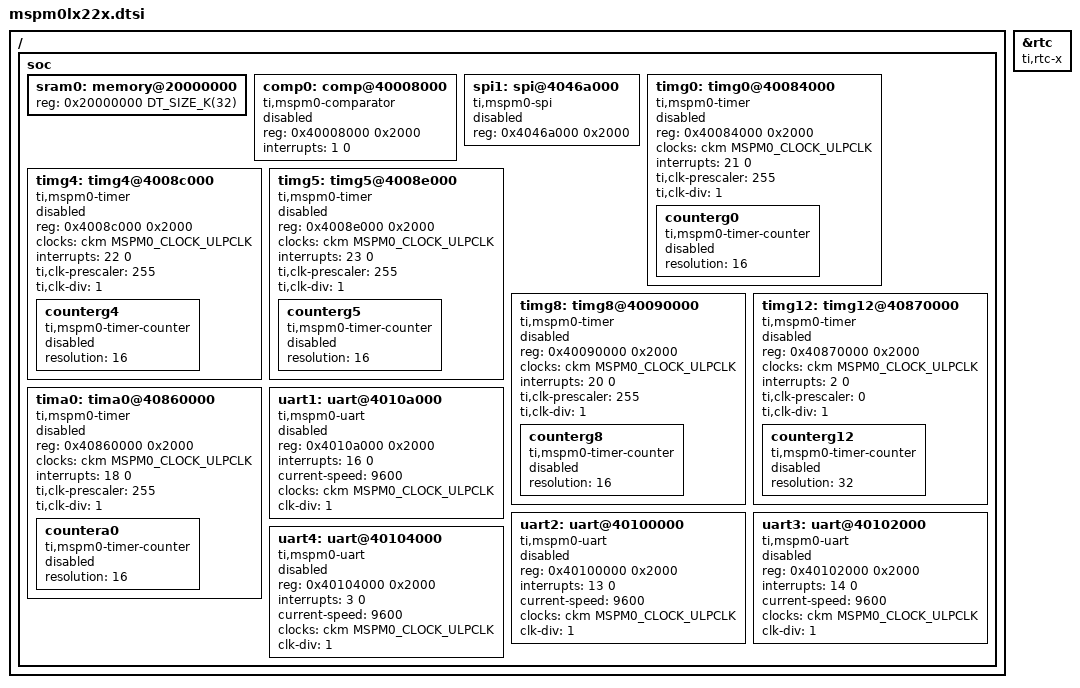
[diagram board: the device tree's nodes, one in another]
/*
 * Copyright (c) 2025-2026 Texas Instruments
 * Copyright (c) 2025 Linumiz GmbH
 *
 * SPDX-License-Identifier: Apache-2.0
 */

#include <mem.h>
#include <ti/mspm0/l/mspm0l.dtsi>

/ {
	soc {
		sram0: memory@20000000 {
			reg = <0x20000000 DT_SIZE_K(32)>;
		};

		comp0: comp@40008000 {
			compatible = "ti,mspm0-comparator";
			reg = <0x40008000 0x2000>;
			interrupts = <1 0>;
			status = "disabled";
		};

		spi1: spi@4046a000 {
			compatible = "ti,mspm0-spi";
			reg = <0x4046a000 0x2000>;
			status = "disabled";
		};

		timg0: timg0@40084000 {
			compatible = "ti,mspm0-timer";
			reg = <0x40084000 0x2000>;
			clocks = <&ckm MSPM0_CLOCK_ULPCLK>;
			interrupts = <21 0>;
			ti,clk-prescaler = <255>;
			ti,clk-div = <1>;
			status = "disabled";

			counterg0: counterg0 {
				compatible = "ti,mspm0-timer-counter";
				resolution = <16>;
				status = "disabled";
			};
		};

		timg4: timg4@4008c000 {
			compatible = "ti,mspm0-timer";
			reg = <0x4008c000 0x2000>;
			clocks = <&ckm MSPM0_CLOCK_ULPCLK>;
			interrupts = <22 0>;
			ti,clk-prescaler = <255>;
			ti,clk-div = <1>;
			status = "disabled";

			counterg4: counterg4 {
				compatible = "ti,mspm0-timer-counter";
				resolution = <16>;
				status = "disabled";
			};
		};

		timg5: timg5@4008e000 {
			compatible = "ti,mspm0-timer";
			reg = <0x4008e000 0x2000>;
			clocks = <&ckm MSPM0_CLOCK_ULPCLK>;
			interrupts = <23 0>;
			ti,clk-prescaler = <255>;
			ti,clk-div = <1>;
			status = "disabled";

			counterg5: counterg5 {
				compatible = "ti,mspm0-timer-counter";
				resolution = <16>;
				status = "disabled";
			};
		};

		timg8: timg8@40090000 {
			compatible = "ti,mspm0-timer";
			reg = <0x40090000 0x2000>;
			clocks = <&ckm MSPM0_CLOCK_ULPCLK>;
			interrupts = <20 0>;
			ti,clk-prescaler = <255>;
			ti,clk-div = <1>;
			status = "disabled";

			counterg8: counterg8 {
				compatible = "ti,mspm0-timer-counter";
				resolution = <16>;
				status = "disabled";
			};
		};

		timg12: timg12@40870000 {
			compatible = "ti,mspm0-timer";
			reg = <0x40870000 0x2000>;
			clocks = <&ckm MSPM0_CLOCK_ULPCLK>;
			interrupts = <2 0>;
			ti,clk-prescaler = <0>; /* No prescaler */
			ti,clk-div = <1>;
			status = "disabled";

			counterg12: counterg12 {
				compatible = "ti,mspm0-timer-counter";
				resolution = <32>;
				status = "disabled";
			};
		};

		tima0: tima0@40860000 {
			compatible = "ti,mspm0-timer";
			reg = <0x40860000 0x2000>;
			clocks = <&ckm MSPM0_CLOCK_ULPCLK>;
			interrupts = <18 0>;
			ti,clk-prescaler = <255>;
			ti,clk-div = <1>;
			status = "disabled";

			countera0: countera0 {
				compatible = "ti,mspm0-timer-counter";
				resolution = <16>;
				status = "disabled";
			};
		};

		uart1: uart@4010a000 {
			compatible = "ti,mspm0-uart";
			reg = <0x4010a000 0x2000>;
			interrupts = <16 0>;
			current-speed = <9600>;
			clocks = <&ckm MSPM0_CLOCK_ULPCLK>;
			clk-div = <1>;
			status = "disabled";
		};

		uart2: uart@40100000 {
			compatible = "ti,mspm0-uart";
			reg = <0x40100000 0x2000>;
			interrupts = <13 0>;
			current-speed = <9600>;
			clocks = <&ckm MSPM0_CLOCK_ULPCLK>;
			clk-div = <1>;
			status = "disabled";
		};

		uart3: uart@40102000 {
			compatible = "ti,mspm0-uart";
			reg = <0x40102000 0x2000>;
			interrupts = <14 0>;
			current-speed = <9600>;
			clocks = <&ckm MSPM0_CLOCK_ULPCLK>;
			clk-div = <1>;
			status = "disabled";
		};

		uart4: uart@40104000 {
			compatible = "ti,mspm0-uart";
			reg = <0x40104000 0x2000>;
			interrupts = <3 0>;
			current-speed = <9600>;
			clocks = <&ckm MSPM0_CLOCK_ULPCLK>;
			clk-div = <1>;
			status = "disabled";
		};
	};
};

&rtc {
	ti,rtc-x;
};
